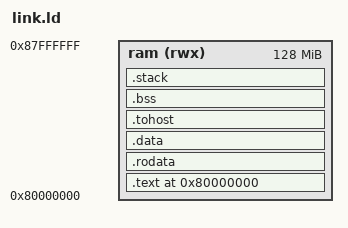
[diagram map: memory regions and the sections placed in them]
/*
 * Copyright (c) 2026 BOSC & ICT, CAS
 * All rights reserved.
 *
 * Redistribution and use in source and binary forms, with or without
 * modification, are permitted provided that the following conditions are
 * met: redistributions of source code must retain the above copyright
 * notice, this list of conditions and the following disclaimer;
 * redistributions in binary form must reproduce the above copyright
 * notice, this list of conditions and the following disclaimer in the
 * documentation and/or other materials provided with the distribution;
 * neither the name of the copyright holders nor the names of its
 * contributors may be used to endorse or promote products derived from
 * this software without specific prior written permission.
 *
 * THIS SOFTWARE IS PROVIDED BY THE COPYRIGHT HOLDERS AND CONTRIBUTORS
 * "AS IS" AND ANY EXPRESS OR IMPLIED WARRANTIES, INCLUDING, BUT NOT
 * LIMITED TO, THE IMPLIED WARRANTIES OF MERCHANTABILITY AND FITNESS FOR
 * A PARTICULAR PURPOSE ARE DISCLAIMED. IN NO EVENT SHALL THE COPYRIGHT
 * OWNER OR CONTRIBUTORS BE LIABLE FOR ANY DIRECT, INDIRECT, INCIDENTAL,
 * SPECIAL, EXEMPLARY, OR CONSEQUENTIAL DAMAGES (INCLUDING, BUT NOT
 * LIMITED TO, PROCUREMENT OF SUBSTITUTE GOODS OR SERVICES; LOSS OF USE,
 * DATA, OR PROFITS; OR BUSINESS INTERRUPTION) HOWEVER CAUSED AND ON ANY
 * THEORY OF LIABILITY, WHETHER IN CONTRACT, STRICT LIABILITY, OR TORT
 * (INCLUDING NEGLIGENCE OR OTHERWISE) ARISING IN ANY WAY OUT OF THE USE
 * OF THIS SOFTWARE, EVEN IF ADVISED OF THE POSSIBILITY OF SUCH DAMAGE.
 */

/* Shared linker layout for the standalone AME examples. */
OUTPUT_ARCH(riscv)
ENTRY(_start)

MEMORY
{
    ram (rwx) : ORIGIN = 0x80000000, LENGTH = 128M
}

SECTIONS
{
    . = ORIGIN(ram);

    .text : ALIGN(16)
    {
        KEEP(*(.text.init))
        *(.text .text.*)
    } > ram

    .rodata : ALIGN(16)
    {
        *(.rodata .rodata.*)
        *(.srodata .srodata.*)
    } > ram

    .data : ALIGN(16)
    {
        __data_start = .;
        PROVIDE(__global_pointer$ = . + 0x800);
        *(.data .data.*)
        *(.sdata .sdata.*)
        __data_end = .;
    } > ram

    .tohost : ALIGN(0x1000)
    {
        KEEP(*(.tohost))
    } > ram

    .bss (NOLOAD) : ALIGN(16)
    {
        __bss_start = .;
        *(.bss .bss.*)
        *(.sbss .sbss.*)
        *(COMMON)
        . = ALIGN(16);
        __bss_end = .;
    } > ram

    .stack (NOLOAD) : ALIGN(16)
    {
        __stack_bottom = .;
        . += 4M;
        __stack_top = .;
    } > ram

    /DISCARD/ :
    {
        *(.comment)
        *(.note .note.*)
        *(.eh_frame .eh_frame.*)
    }
}
